# f28p65x_escss_config_regs register map
Vendor: Texas Instruments
Peripheral module from a debugger description file (folder C2000).
Address unit: 16 bits
Registers are 32-bit, read-write, no defined reset value unless marked. A register's access mark holds for its fields unless they carry their own. Offsets are as the file gives them; lines under a group give offsets from that group; [hi:lo] are bit positions; {n}, {i} and the like mark numbered series; 'fields as' and 'values as' point back to an identical list; <NAME> marks a mode.

## ESCSS_CONFIG_REGS — ESCSS CONFIG Registers
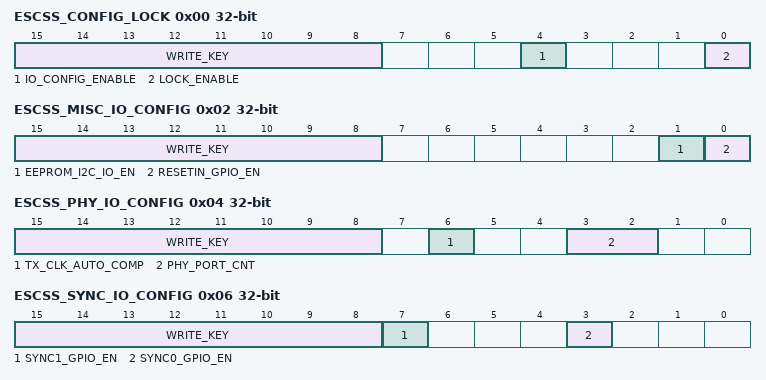
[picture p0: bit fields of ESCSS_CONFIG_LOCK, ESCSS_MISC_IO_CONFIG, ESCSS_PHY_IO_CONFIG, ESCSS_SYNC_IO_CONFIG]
0x00 ESCSS_CONFIG_LOCK — EtherCATSS Configuration Lock
  [15:8] WRITE_KEY — Key to enable writing lock
  [4] IO_CONFIG_ENABLE — Locking the IO Configuration
  [0] LOCK_ENABLE — Locking writes to ECATSS
0x02 ESCSS_MISC_IO_CONFIG — RESET_IN, EEPROM IO connections select
  [15:8] WRITE_KEY — Key to enable writing lock
  [1] EEPROM_I2C_IO_EN — Enables the EEPROM I2C IOPAD connection
  [0] RESETIN_GPIO_EN — Enabled ResetIN from GPIO
0x04 ESCSS_PHY_IO_CONFIG — Control Register of ESCSS
  [15:8] WRITE_KEY — Key to enable writing lock
  [6] TX_CLK_AUTO_COMP — Selects TX_CLK IO to do Auto compensation
  [3:2] PHY_PORT_CNT — Number of PHY port counts
0x06 ESCSS_SYNC_IO_CONFIG — SYNC Signals IO configurations
  [15:8] WRITE_KEY — Key to enable writing lock
  [7] SYNC1_GPIO_EN — SYNC1 connection to OUT pad enabled
  [3] SYNC0_GPIO_EN — SYNC0 connection to OUT pad enabled
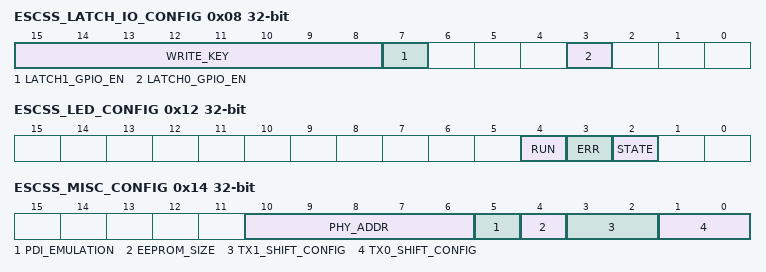
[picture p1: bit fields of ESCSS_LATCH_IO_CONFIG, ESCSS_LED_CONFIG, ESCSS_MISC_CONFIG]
0x08 ESCSS_LATCH_IO_CONFIG — LATCH inputs IO pad select
  [15:8] WRITE_KEY — Key to enable writing lock
  [7] LATCH1_GPIO_EN — LATCH1 connection to IN pad enabled
  [3] LATCH0_GPIO_EN — LATCH0 connection to IN pad enabled
0x0A ESCSS_GPIN_SEL — GPIN Select between IO PAD and tieoff
  [31:0] GPIN_SEL — Enable for GPI Connection to IO pad.
0x0E ESCSS_GPOUT_SEL — GPOUT IO pad connect select
  [31:0] GPOUT_SEL — GPO selection between register or GPIO pad.
0x12 ESCSS_LED_CONFIG — Selection of LED o/p connect to IO pad
  [4] RUN — GPIO enable for RUN LED
  [3] ERR — GPIO enable for ERR LED
  [2] STATE — GPIO enable for STATE LED
0x14 ESCSS_MISC_CONFIG — Miscelleneous Configuration
  [10:6] PHY_ADDR — PHY Address Offset
  [5] PDI_EMULATION — PDI Emulation enable
  [4] EEPROM_SIZE — EEPROM Size bound select
  [3:2] TX1_SHIFT_CONFIG — TX Shift configuration for Port1
  [1:0] TX0_SHIFT_CONFIG — TX Shift configuration for Port0
